# MSPM0G350X register map
Vendor: Texas Instruments; File version: This preliminary header file does not have a version number - build date: 2023-02-21 16:25:48
CPU: CM0 r0p1, little endian, MPU, no FPU, 3 interrupt priority bits
Registers are 32-bit, read-write, reset 0x0 unless marked. A register's access mark holds for its fields unless they carry their own. Offsets are from the block's base; [hi:lo] are bit positions.

## DAC0 — PERIPHERALREGION
Base 0x40018000
0x400 FSUB_0 — Subscriber Port 0
  [3:0] FSUB_0_CHANID — 0 = disconnected. others = connected to channel_ID = CHANID.
    0=FSUB_0_CHANID_UNCONNECTED (UNCONNECTED)
0x404 FSUB_1 — Subscriber Port 1
  [3:0] FSUB_1_CHANID — 0 = disconnected. others = connected to channel_ID = CHANID.
    0=FSUB_1_CHANID_UNCONNECTED (UNCONNECTED)
0x444 FPUB_1 — Publisher port 1
  [3:0] FPUB_1_CHANID — 0 = disconnected. others = connected to channel_ID = CHANID.
    0=FPUB_1_CHANID_UNCONNECTED (UNCONNECTED)
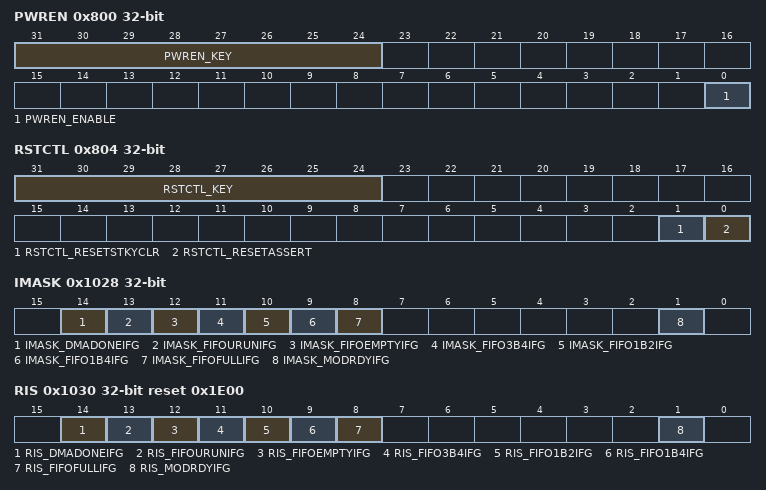
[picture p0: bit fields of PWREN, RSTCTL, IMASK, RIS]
0x800 PWREN — Power enable
  [31:24] PWREN_KEY wo — KEY to allow Power State Change
    38=PWREN_KEY_UNLOCK_W (_TO_UNLOCK_W_)
  [0] PWREN_ENABLE — Enable the power
    0=PWREN_ENABLE_DISABLE (DISABLE); 1=PWREN_ENABLE_ENABLE (ENABLE)
0x804 RSTCTL wo — Reset Control
  [31:24] RSTCTL_KEY — Unlock key
    177=RSTCTL_KEY_UNLOCK_W (_TO_UNLOCK_W_)
  [1] RSTCTL_RESETSTKYCLR — Clear the RESETSTKY bit in the STAT register
    0=RSTCTL_RESETSTKYCLR_NOP (NOP); 1=RSTCTL_RESETSTKYCLR_CLR (CLR)
  [0] RSTCTL_RESETASSERT — Assert reset to the peripheral
    0=RSTCTL_RESETASSERT_NOP (NOP); 1=RSTCTL_RESETASSERT_ASSERT (ASSERT)
0x814 STAT ro — Status Register
  [16] STAT_RESETSTKY — This bit indicates, if the peripheral was reset, since this bit was cleared by RESETSTKYCLR in the RSTCTL register
    0=STAT_RESETSTKY_NORES (NORES); 1=STAT_RESETSTKY_RESET (RESET)
0x1020 IIDX ro — Interrupt index
  [3:0] IIDX_STAT — Interrupt index status
    0=IIDX_STAT_NO_INTR (NO_INTR); 2=IIDX_STAT_MODRDYIFG (MODRDYIFG); 9=IIDX_STAT_FIFOFULLIFG (FIFOFULLIFG); 10=IIDX_STAT_FIFO1B4IFG (FIFO1B4IFG); 11=IIDX_STAT_FIFO1B2IFG (FIFO1B2IFG); 12=IIDX_STAT_FIFO3B4IFG (FIFO3B4IFG); 13=IIDX_STAT_FIFOEMPTYIFG (FIFOEMPTYIFG); 14=IIDX_STAT_FIFOURUNIFG (FIFOURUNIFG); 15=IIDX_STAT_DMADONEIFG (DMADONEIFG)
0x1028 IMASK — Interrupt mask
  [14] IMASK_DMADONEIFG — Masks DMADONEIFG
    0=IMASK_DMADONEIFG_CLR (CLR); 1=IMASK_DMADONEIFG_SET (SET)
  [13] IMASK_FIFOURUNIFG — Masks FIFOURUNIFG
    0=IMASK_FIFOURUNIFG_CLR (CLR); 1=IMASK_FIFOURUNIFG_SET (SET)
  [12] IMASK_FIFOEMPTYIFG — Masks FIFOEMPTYIFG
    0=IMASK_FIFOEMPTYIFG_CLR (CLR); 1=IMASK_FIFOEMPTYIFG_SET (SET)
  [11] IMASK_FIFO3B4IFG — Masks FIFO3B4IFG
    0=IMASK_FIFO3B4IFG_CLR (CLR); 1=IMASK_FIFO3B4IFG_SET (SET)
  [10] IMASK_FIFO1B2IFG — Masks FIFO1B2IFG
    0=IMASK_FIFO1B2IFG_CLR (CLR); 1=IMASK_FIFO1B2IFG_SET (SET)
  [9] IMASK_FIFO1B4IFG — Masks FIFO1B4IFG
    0=IMASK_FIFO1B4IFG_CLR (CLR); 1=IMASK_FIFO1B4IFG_SET (SET)
  [8] IMASK_FIFOFULLIFG — Masks FIFOFULLIFG
    0=IMASK_FIFOFULLIFG_CLR (CLR); 1=IMASK_FIFOFULLIFG_SET (SET)
  [1] IMASK_MODRDYIFG — Masks MODRDYIFG
    0=IMASK_MODRDYIFG_CLR (CLR); 1=IMASK_MODRDYIFG_SET (SET)
0x1030 RIS ro reset 0x1E00 — Raw interrupt status
  [14] RIS_DMADONEIFG — Raw interrupt status for DMADONEIFG
    0=RIS_DMADONEIFG_CLR (CLR); 1=RIS_DMADONEIFG_SET (SET)
  [13] RIS_FIFOURUNIFG — Raw interrupt status for FIFOURUNIFG
    0=RIS_FIFOURUNIFG_CLR (CLR); 1=RIS_FIFOURUNIFG_SET (SET)
  [12] RIS_FIFOEMPTYIFG — Raw interrupt status for FIFOEMPTYIFG
    0=RIS_FIFOEMPTYIFG_CLR (CLR); 1=RIS_FIFOEMPTYIFG_SET (SET)
  [11] RIS_FIFO3B4IFG — Raw interrupt status for FIFO3B4IFG
    0=RIS_FIFO3B4IFG_CLR (CLR); 1=RIS_FIFO3B4IFG_SET (SET)
  [10] RIS_FIFO1B2IFG — Raw interrupt status for FIFO1B2IFG
    0=RIS_FIFO1B2IFG_CLR (CLR); 1=RIS_FIFO1B2IFG_SET (SET)
  [9] RIS_FIFO1B4IFG — Raw interrupt status for FIFO1B4IFG
    0=RIS_FIFO1B4IFG_CLR (CLR); 1=RIS_FIFO1B4IFG_SET (SET)
  [8] RIS_FIFOFULLIFG — Raw interrupt status for FIFOFULLIFG
    0=RIS_FIFOFULLIFG_CLR (CLR); 1=RIS_FIFOFULLIFG_SET (SET)
  [1] RIS_MODRDYIFG — Raw interrupt status for MODRDYIFG
    0=RIS_MODRDYIFG_CLR (CLR); 1=RIS_MODRDYIFG_SET (SET)
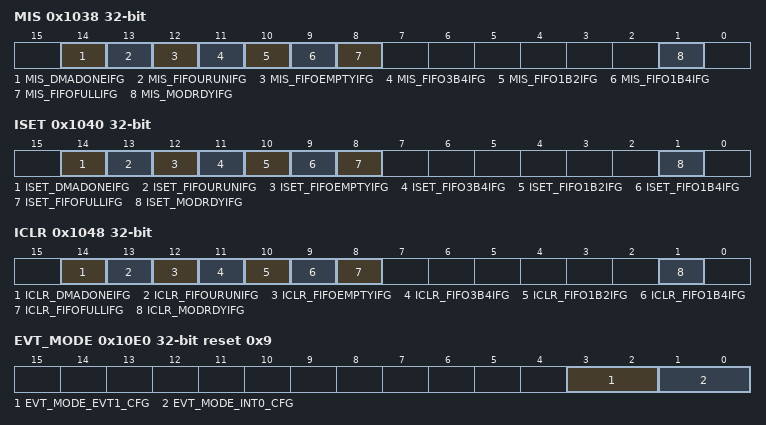
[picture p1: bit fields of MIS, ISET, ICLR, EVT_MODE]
0x1038 MIS ro — Masked interrupt status
  [14] MIS_DMADONEIFG — Masked interrupt status for DMADONEIFG
    0=MIS_DMADONEIFG_CLR (CLR); 1=MIS_DMADONEIFG_SET (SET)
  [13] MIS_FIFOURUNIFG — Masked interrupt status for FIFOURUNIFG
    0=MIS_FIFOURUNIFG_CLR (CLR); 1=MIS_FIFOURUNIFG_SET (SET)
  [12] MIS_FIFOEMPTYIFG — Masked interrupt status for FIFOEMPTYIFG
    0=MIS_FIFOEMPTYIFG_CLR (CLR); 1=MIS_FIFOEMPTYIFG_SET (SET)
  [11] MIS_FIFO3B4IFG — Masked interrupt status for FIFO3B4IFG
    0=MIS_FIFO3B4IFG_CLR (CLR); 1=MIS_FIFO3B4IFG_SET (SET)
  [10] MIS_FIFO1B2IFG — Masked interrupt status for FIFO1B2IFG
    0=MIS_FIFO1B2IFG_CLR (CLR); 1=MIS_FIFO1B2IFG_SET (SET)
  [9] MIS_FIFO1B4IFG — Masked interrupt status for FIFO1B4IFG
    0=MIS_FIFO1B4IFG_CLR (CLR); 1=MIS_FIFO1B4IFG_SET (SET)
  [8] MIS_FIFOFULLIFG — Masked interrupt status for FIFOFULLIFG
    0=MIS_FIFOFULLIFG_CLR (CLR); 1=MIS_FIFOFULLIFG_SET (SET)
  [1] MIS_MODRDYIFG — Masked interrupt status for MODRDYIFG
    0=MIS_MODRDYIFG_CLR (CLR); 1=MIS_MODRDYIFG_SET (SET)
0x1040 ISET wo — Interrupt set
  [14] ISET_DMADONEIFG — Sets DMADONEIFG in RIS register
    0=ISET_DMADONEIFG_NO_EFFECT (NO_EFFECT); 1=ISET_DMADONEIFG_SET (SET)
  [13] ISET_FIFOURUNIFG — Sets FIFOURUNIFG in RIS register
    0=ISET_FIFOURUNIFG_NO_EFFECT (NO_EFFECT); 1=ISET_FIFOURUNIFG_SET (SET)
  [12] ISET_FIFOEMPTYIFG — Sets FIFOEMPTYIFG in RIS register
    0=ISET_FIFOEMPTYIFG_NO_EFFECT (NO_EFFECT); 1=ISET_FIFOEMPTYIFG_SET (SET)
  [11] ISET_FIFO3B4IFG — Sets FIFO3B4IFG in RIS register
    0=ISET_FIFO3B4IFG_NO_EFFECT (NO_EFFECT); 1=ISET_FIFO3B4IFG_SET (SET)
  [10] ISET_FIFO1B2IFG — Sets FIFO1B2IFG in RIS register
    0=ISET_FIFO1B2IFG_NO_EFFECT (NO_EFFECT); 1=ISET_FIFO1B2IFG_SET (SET)
  [9] ISET_FIFO1B4IFG — Sets FIFO1B4IFG in RIS register
    0=ISET_FIFO1B4IFG_NO_EFFECT (NO_EFFECT); 1=ISET_FIFO1B4IFG_SET (SET)
  [8] ISET_FIFOFULLIFG — Sets FIFOFULLIFG in RIS register
    0=ISET_FIFOFULLIFG_NO_EFFECT (NO_EFFECT); 1=ISET_FIFOFULLIFG_SET (SET)
  [1] ISET_MODRDYIFG — Sets MODRDYIFG in RIS register
    0=ISET_MODRDYIFG_NO_EFFECT (NO_EFFECT); 1=ISET_MODRDYIFG_SET (SET)
0x1048 ICLR wo — Interrupt clear
  [14] ICLR_DMADONEIFG — Clears DMADONEIFG in RIS register
    0=ICLR_DMADONEIFG_NO_EFFECT (NO_EFFECT); 1=ICLR_DMADONEIFG_CLR (CLR)
  [13] ICLR_FIFOURUNIFG — Clears FIFOURUNIFG in RIS register
    0=ICLR_FIFOURUNIFG_NO_EFFECT (NO_EFFECT); 1=ICLR_FIFOURUNIFG_CLR (CLR)
  [12] ICLR_FIFOEMPTYIFG — Clears FIFOEMPTYIFG in RIS register
    0=ICLR_FIFOEMPTYIFG_NO_EFFECT (NO_EFFECT); 1=ICLR_FIFOEMPTYIFG_CLR (CLR)
  [11] ICLR_FIFO3B4IFG — Clears FIFO3B4IFG in RIS register
    0=ICLR_FIFO3B4IFG_NO_EFFECT (NO_EFFECT); 1=ICLR_FIFO3B4IFG_CLR (CLR)
  [10] ICLR_FIFO1B2IFG — Clears FIFO1B2IFG in RIS register
    0=ICLR_FIFO1B2IFG_NO_EFFECT (NO_EFFECT); 1=ICLR_FIFO1B2IFG_CLR (CLR)
  [9] ICLR_FIFO1B4IFG — Clears FIFO1B4IFG in RIS register
    0=ICLR_FIFO1B4IFG_NO_EFFECT (NO_EFFECT); 1=ICLR_FIFO1B4IFG_CLR (CLR)
  [8] ICLR_FIFOFULLIFG — Clears FIFOFULLIFG in RIS register
    0=ICLR_FIFOFULLIFG_NO_EFFECT (NO_EFFECT); 1=ICLR_FIFOFULLIFG_CLR (CLR)
  [1] ICLR_MODRDYIFG — Clears MODRDYIFG in RIS register
    0=ICLR_MODRDYIFG_NO_EFFECT (NO_EFFECT); 1=ICLR_MODRDYIFG_CLR (CLR)
0x10E0 EVT_MODE reset 0x9 — Event Mode
  [3:2] EVT_MODE_EVT1_CFG ro — Event line mode select for event corresponding to [IPSTANDARD.INT_EVENT][0]
    0=EVT_MODE_EVT1_CFG_DISABLE (DISABLE); 1=EVT_MODE_EVT1_CFG_SOFTWARE (SOFTWARE); 2=EVT_MODE_EVT1_CFG_HARDWARE (HARDWARE)
  [1:0] EVT_MODE_INT0_CFG ro — Event line mode select for event corresponding to [IPSTANDARD.INT_EVENT][0]
    0=EVT_MODE_INT0_CFG_DISABLE (DISABLE); 1=EVT_MODE_INT0_CFG_SOFTWARE (SOFTWARE); 2=EVT_MODE_INT0_CFG_HARDWARE (HARDWARE)
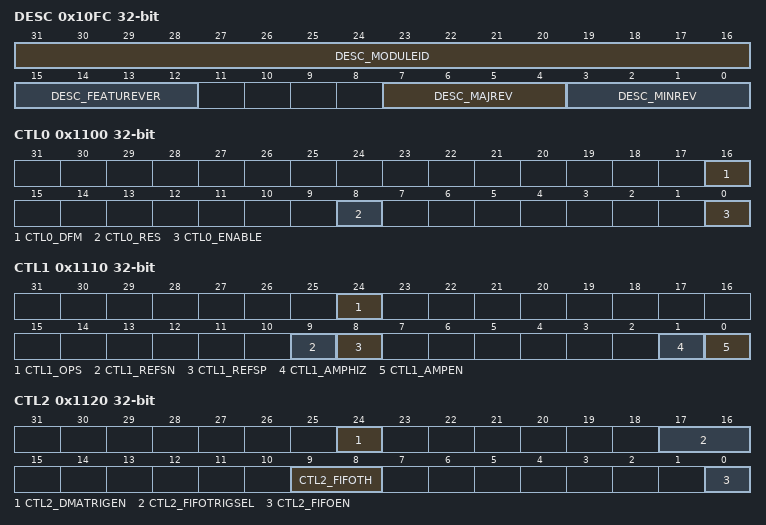
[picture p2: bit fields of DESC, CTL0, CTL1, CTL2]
0x10FC DESC ro — Module Description
  [31:16] DESC_MODULEID — Module identification contains a unique peripheral identification number. The assignments are maintained in a central database for all of the platform modules to ensure uniqueness.
  [15:12] DESC_FEATUREVER — Feature Set for the module *instance*
  [7:4] DESC_MAJREV — Major rev of the IP
  [3:0] DESC_MINREV — Minor rev of the IP
0x1100 CTL0 — Control 0
  [16] CTL0_DFM — This bit defines the DAC input data format.
    0=CTL0_DFM_BINARY (BINARY); 1=CTL0_DFM_TWOS_COMP (TWOS_COMP)
  [8] CTL0_RES — These bits define the DAC output voltage resolution.
    0=CTL0_RES__8BITS (_8BITS); 1=CTL0_RES__12BITS (_12BITS)
  [0] CTL0_ENABLE — This bit enables the DAC module.
    0=CTL0_ENABLE_CLR (CLR); 1=CTL0_ENABLE_SET (SET)
0x1110 CTL1 — Control 1
  [24] CTL1_OPS — These bits select the DAC output on device pin.
    0=CTL1_OPS_NOC0 (NOC0); 1=CTL1_OPS_OUT0 (OUT0)
  [9] CTL1_REFSN — This bit selects the DAC voltage reference source + input.
    0=CTL1_REFSN_VEREFN (VEREFN); 1=CTL1_REFSN_VSSA (VSSA)
  [8] CTL1_REFSP — This bit selects the DAC voltage reference source + input.
    0=CTL1_REFSP_VDDA (VDDA); 1=CTL1_REFSP_VEREFP (VEREFP)
  [1] CTL1_AMPHIZ — AMPHIZ - amplifier output value 0 : amplifier output is high impedance 1 : amplifier output is pulled down to ground
    0=CTL1_AMPHIZ_HIZ (HIZ); 1=CTL1_AMPHIZ_PULLDOWN (PULLDOWN)
  [0] CTL1_AMPEN — AMP_EN - output amplifier enabled or disabled 0 : disabled 1 : enabled
    0=CTL1_AMPEN_DISABLE (DISABLE); 1=CTL1_AMPEN_ENABLE (ENABLE)
0x1120 CTL2 — Control 2
  [24] CTL2_DMATRIGEN — This bit enables the DMA trigger generation mechanism. When this bit is set along with FIFOEN, the DMA trigger is generated based on the empty FIFO locations qualified by FIFOTH settings. This bit needs to be cleared by SW to stop further DMA triggers
    0=CTL2_DMATRIGEN_CLR (CLR); 1=CTL2_DMATRIGEN_SET (SET)
  [17:16] CTL2_FIFOTRIGSEL — These bits select the source for FIFO read trigger. When the selected FIFO read trigger is asserted, the data from FIFO (as indicated by read pointer) is moved into internal DAC data register.
    0=CTL2_FIFOTRIGSEL_STIM (STIM); 1=CTL2_FIFOTRIGSEL_TRIG0 (TRIG0); 2=CTL2_FIFOTRIGSEL_TRIG1 (TRIG1); 3=CTL2_FIFOTRIGSEL_SPARE (SPARE)
  [9:8] CTL2_FIFOTH — These bits determine the FIFO threshold. In case of DMA based operation, DAC generates new DMA trigger when the number of empty locations in FIFO match the selected FIFO threshold level. In case of CPU based operation, the FIFO threshold bits are don't care and FIFO level is directly indicated through the respective bits in the RIS register.
    0=CTL2_FIFOTH_LOW (LOW); 1=CTL2_FIFOTH_MED (MED); 2=CTL2_FIFOTH_HIGH (HIGH); 3=CTL2_FIFOTH_SPARE (SPARE)
  [0] CTL2_FIFOEN — This bit enables the FIFO and the FIFO hardware control state machine.
    0=CTL2_FIFOEN_CLR (CLR); 1=CTL2_FIFOEN_SET (SET)
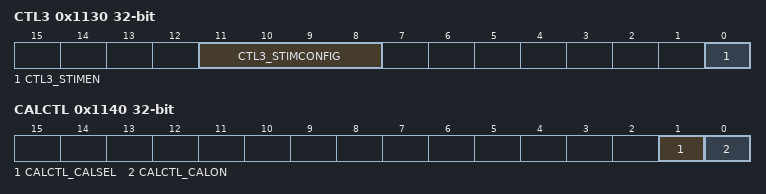
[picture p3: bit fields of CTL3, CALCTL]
0x1130 CTL3 — Control 3
  [11:8] CTL3_STIMCONFIG — These bits are used to configure the trigger rate from the sample time generator. The STIMCONFIG values 10 to 15 are reserved and default to same effect as value 0 (500SPS).
    0=CTL3_STIMCONFIG__500SPS (_500SPS); 1=CTL3_STIMCONFIG__1KSPS (_1KSPS); 2=CTL3_STIMCONFIG__2KSPS (_2KSPS); 3=CTL3_STIMCONFIG__4KSPS (_4KSPS); 4=CTL3_STIMCONFIG__8KSPS (_8KSPS); 5=CTL3_STIMCONFIG__16KSPS (_16KSPS); 6=CTL3_STIMCONFIG__100KSPS (_100KSPS); 7=CTL3_STIMCONFIG__200KSPS (_200KSPS); 8=CTL3_STIMCONFIG__500KSPS (_500KSPS); 9=CTL3_STIMCONFIG__1MSPS (_1MSPS)
  [0] CTL3_STIMEN — This bit enables the sample time generator.
    0=CTL3_STIMEN_CLR (CLR); 1=CTL3_STIMEN_SET (SET)
0x1140 CALCTL — Calibration control
  [1] CALCTL_CALSEL — This bit is used to select between factory trim or self calibration trim.
    0=CALCTL_CALSEL_FACTORYTRIM (FACTORY_TRIM); 1=CALCTL_CALSEL_SELFCALIBRATIONTRIM (SELF_CALIBRATION_TRIM)
  [0] CALCTL_CALON — This bit when set initiates the DAC offset error calibration sequence and is automatically reset when the offset error calibration completes.
    0=CALCTL_CALON_INACTIVE (INACTIVE); 1=CALCTL_CALON_ACTIVE (ACTIVE)
0x1160 CALDATA ro — Calibration data
  [6:0] CALDATA_DATA — DAC offset error calibration data. The DAC offset error calibration data is represented in twos complement format providing a range of 64 to +63. This is read-only bit, reflecting the calibration data. Writing to this register will have no effect, it will not change the calibration value.
0x1200 DATA0
  [11:0] DATA0_DATA_VALUE — This is the data written for digital to analog conversion.
